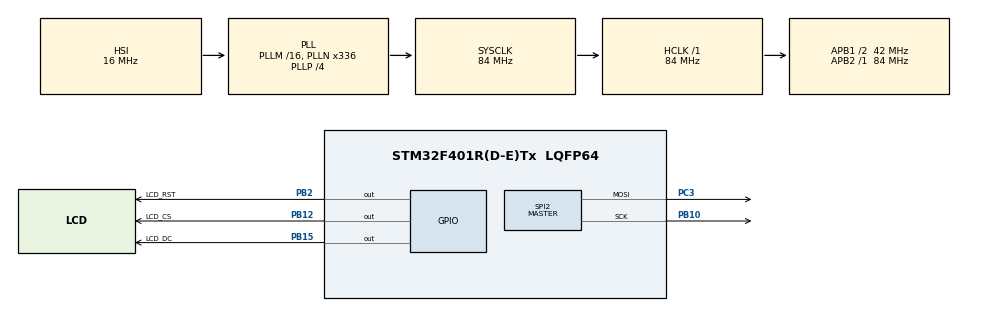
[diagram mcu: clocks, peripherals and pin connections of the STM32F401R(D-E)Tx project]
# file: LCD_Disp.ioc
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Dma.Request0=SPI2_TX
Dma.SPI2_TX.0.Direction=DMA_MEMORY_TO_PERIPH
Dma.SPI2_TX.0.FIFOMode=DMA_FIFOMODE_DISABLE
Dma.SPI2_TX.0.Instance=DMA1_Stream4
Dma.SPI2_TX.0.MemDataAlignment=DMA_MDATAALIGN_BYTE
Dma.SPI2_TX.0.MemInc=DMA_MINC_ENABLE
Dma.SPI2_TX.0.Mode=DMA_NORMAL
Dma.SPI2_TX.0.PeriphDataAlignment=DMA_PDATAALIGN_BYTE
Dma.SPI2_TX.0.PeriphInc=DMA_PINC_DISABLE
Dma.SPI2_TX.0.Priority=DMA_PRIORITY_LOW
Mcu.Family=STM32F4
Mcu.Name=STM32F401R(D-E)Tx
Mcu.Package=LQFP64
NVIC.DMA1_Stream4_IRQn=true\:0\:0\:false\:false\:true\:false\:true\:true
NVIC.PriorityGroup=NVIC_PRIORITYGROUP_4
PA13.Mode=Serial_Wire
PA13.Signal=SYS_JTMS-SWDIO
PA14.Mode=Serial_Wire
PA14.Signal=SYS_JTCK-SWCLK
PB10.Mode=TX_Only_Simplex_Unidirect_Master
PB10.Signal=SPI2_SCK
PB12.GPIO_Label=LCD_CS
PB12.PinState=GPIO_PIN_SET
PB12.Signal=GPIO_Output
PB15.GPIO_Label=LCD_DC
PB15.Signal=GPIO_Output
PB2.GPIO_Label=LCD_RST
PB2.Signal=GPIO_Output
PC3.Mode=TX_Only_Simplex_Unidirect_Master
PC3.Signal=SPI2_MOSI
ProjectManager.HeapSize=0x200
ProjectManager.StackSize=0x2000
ProjectManager.TargetToolchain=STM32CubeIDE
RCC.48MHZClocksFreq_Value=48000000
RCC.AHBFreq_Value=84000000
RCC.APB1CLKDivider=RCC_HCLK_DIV2
RCC.APB1Freq_Value=42000000
RCC.APB1TimFreq_Value=84000000
RCC.APB2Freq_Value=84000000
RCC.APB2TimFreq_Value=84000000
RCC.CortexFreq_Value=84000000
RCC.HCLKFreq_Value=84000000
RCC.HSE_VALUE=8000000
RCC.HSI_VALUE=16000000
RCC.LSE_VALUE=32768
RCC.PLLN=336
RCC.PLLP=RCC_PLLP_DIV4
RCC.PLLQ=7
RCC.SYSCLKFreq_VALUE=84000000
RCC.SYSCLKSource=RCC_SYSCLKSOURCE_PLLCLK
RCC.VCOOutputFreq_Value=336000000
SPI2.BaudRatePrescaler=SPI_BAUDRATEPRESCALER_8
SPI2.Direction=SPI_DIRECTION_2LINES
SPI2.Mode=SPI_MODE_MASTER
SPI2.VirtualType=VM_MASTER
board=NUCLEO-F401RE

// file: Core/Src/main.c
/* USER CODE BEGIN Header */
/**
  ******************************************************************************
  * @file           : main.c
  * @brief          : Main program body
  ******************************************************************************
  * @attention
  *
  * Copyright (c) 2026 STMicroelectronics.
  * All rights reserved.
  *
  * This software is licensed under terms that can be found in the LICENSE file
  * in the root directory of this software component.
  * If no LICENSE file comes with this software, it is provided AS-IS.
  *
  ******************************************************************************
  */
/* USER CODE END Header */
#include "main.h"
#include "dma.h"
#include "spi.h"
#include "gpio.h"

/* USER CODE BEGIN Includes */
#include "lcd.h"
#include "hagl.h"
#include "font6x9.h"
#include "rgb565.h"
#include "metaballs.h"
#include <stdlib.h>
/* USER CODE END Includes */

void SystemClock_Config(void);

void HAL_SPI_TxCpltCallback(SPI_HandleTypeDef *hspi)
	{
		if (hspi == &hspi2)
		{
			lcd_transfer_done();
		}
	}

/* USER CODE BEGIN 0 */
uint16_t test_image[64*64];
/* USER CODE END 0 */

int main(void)
{

  /* MCU Configuration--------------------------------------------------------*/

  /* Reset of all peripherals, Initializes the Flash interface and the Systick. */
  HAL_Init();

  /* Configure the system clock */
  SystemClock_Config();

  /* Initialize all configured peripherals */
  MX_GPIO_Init();
  MX_DMA_Init();
  MX_SPI2_Init();

  /* Infinite loop */
  /* USER CODE BEGIN WHILE */
//  lcd_init();
//  for (int i = 0; i < 8; i++) {
//    hagl_draw_rounded_rectangle(2+i, 2+i, 158-i, 126-i, 8-i, rgb565(0, 0, i*16));
//  }
//  hagl_put_text(L"Hello World!", 40, 55, YELLOW, font6x9);
//  lcd_copy();
  lcd_init();
  hagl_fill_circle(64,64,20,(rand() % 0xffff));
  hagl_fill_circle(64,64,20,0);
  hagl_fill_circle(20,20,5,rand() % 0xffff);
  lcd_copy();

  while (1)
  {

    /* USER CODE END WHILE */

  }
}

void SystemClock_Config(void)
{
  RCC_OscInitTypeDef RCC_OscInitStruct = {0};
  RCC_ClkInitTypeDef RCC_ClkInitStruct = {0};

  /** Configure the main internal regulator output voltage
  */
  __HAL_RCC_PWR_CLK_ENABLE();
  __HAL_PWR_VOLTAGESCALING_CONFIG(PWR_REGULATOR_VOLTAGE_SCALE2);

  /** Initializes the RCC Oscillators according to the specified parameters
  * in the RCC_OscInitTypeDef structure.
  */
  RCC_OscInitStruct.OscillatorType = RCC_OSCILLATORTYPE_HSI;
  RCC_OscInitStruct.HSIState = RCC_HSI_ON;
  RCC_OscInitStruct.HSICalibrationValue = RCC_HSICALIBRATION_DEFAULT;
  RCC_OscInitStruct.PLL.PLLState = RCC_PLL_ON;
  RCC_OscInitStruct.PLL.PLLSource = RCC_PLLSOURCE_HSI;
  RCC_OscInitStruct.PLL.PLLM = 16;
  RCC_OscInitStruct.PLL.PLLN = 336;
  RCC_OscInitStruct.PLL.PLLP = RCC_PLLP_DIV4;
  RCC_OscInitStruct.PLL.PLLQ = 7;
  if (HAL_RCC_OscConfig(&RCC_OscInitStruct) != HAL_OK)
  {
    Error_Handler();
  }

  /** Initializes the CPU, AHB and APB buses clocks
  */
  RCC_ClkInitStruct.ClockType = RCC_CLOCKTYPE_HCLK|RCC_CLOCKTYPE_SYSCLK
                              |RCC_CLOCKTYPE_PCLK1|RCC_CLOCKTYPE_PCLK2;
  RCC_ClkInitStruct.SYSCLKSource = RCC_SYSCLKSOURCE_PLLCLK;
  RCC_ClkInitStruct.AHBCLKDivider = RCC_SYSCLK_DIV1;
  RCC_ClkInitStruct.APB1CLKDivider = RCC_HCLK_DIV2;
  RCC_ClkInitStruct.APB2CLKDivider = RCC_HCLK_DIV1;

  if (HAL_RCC_ClockConfig(&RCC_ClkInitStruct, FLASH_LATENCY_2) != HAL_OK)
  {
    Error_Handler();
  }
}

void Error_Handler(void)
{
  __disable_irq();
  while (1)
  {
  }
}
